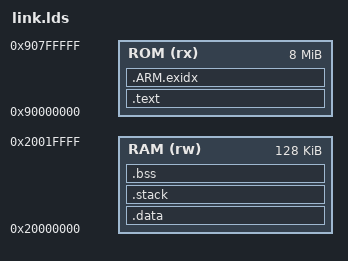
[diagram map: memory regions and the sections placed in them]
/*
 * linker script for STM32F4xx with GNU ld
 * bernard.xiong 2009-10-14
 */

/* Program Entry, set to mark it as "used" and avoid gc */
MEMORY
{
    /* XIP from external W25Q64 via QUADSPI memory-mapped window.            */
    /* Application is loaded by the bootloader at 0x08000000 which maps      */
    /* the QSPI flash here. See bootloader/src/w25q64.c.                     */
    ROM (rx) : ORIGIN = 0x90000000, LENGTH =    8M /* W25Q64: 8MB */
    RAM (rw) : ORIGIN = 0x20000000, LENGTH =  128k /* DTCM       */
}
ENTRY(Reset_Handler)
/* RT-Thread switches to per-thread stacks once scheduling starts, but the
 * startup stack must accommodate HAL_Init + SystemClock_Config (which calls
 * PeriphCommonClock_Config / HAL_RCCEx_PeriphCLKConfig / RCCEx_PLL2_Config /
 * HAL_GetTick nested) -- empirically ~700 bytes. The previous 0x200 limit
 * silently overflowed into the tail of .data (_object_container[Memory]),
 * which then made rt_smem_init's RT_ASSERT(information != NULL) fail. */
_system_stack_size = 0x800;

SECTIONS
{
    .text :
    {
        . = ALIGN(4);
        _stext = .;
        KEEP(*(.isr_vector))            /* Startup code */

        . = ALIGN(4);
        *(.text)                        /* remaining code */
        *(.text.*)                      /* remaining code */
        *(.rodata)                      /* read-only data (constants) */
        *(.rodata*)
        *(.glue_7)
        *(.glue_7t)
        *(.gnu.linkonce.t*)

        /* section information for finsh shell */
        . = ALIGN(4);
        __fsymtab_start = .;
        KEEP(*(FSymTab))
        __fsymtab_end = .;

        . = ALIGN(4);
        __vsymtab_start = .;
        KEEP(*(VSymTab))
        __vsymtab_end = .;

        /* section information for initial. */
        . = ALIGN(4);
        __rt_init_start = .;
        KEEP(*(SORT(.rti_fn*)))
        __rt_init_end = .;

        . = ALIGN(4);

        PROVIDE(__ctors_start__ = .);
        KEEP (*(SORT(.init_array.*)))
        KEEP (*(.init_array))
        PROVIDE(__ctors_end__ = .);

        . = ALIGN(4);

        _etext = .;
    } > ROM = 0

    /* .ARM.exidx is sorted, so has to go in its own output section.  */
    __exidx_start = .;
    .ARM.exidx :
    {
        *(.ARM.exidx* .gnu.linkonce.armexidx.*)

        /* This is used by the startup in order to initialize the .data secion */
        _sidata = .;
    } > ROM
    __exidx_end = .;

    /* .data section which is used for initialized data */

    .data : AT (_sidata)
    {
        . = ALIGN(4);
        /* This is used by the startup in order to initialize the .data secion */
        _sdata = . ;

        *(.data)
        *(.data.*)
        *(.gnu.linkonce.d*)

        PROVIDE(__dtors_start__ = .);
        KEEP(*(SORT(.dtors.*)))
        KEEP(*(.dtors))
        PROVIDE(__dtors_end__ = .);

        . = ALIGN(4);
        /* This is used by the startup in order to initialize the .data secion */
        _edata = . ;
    } >RAM

    .stack :
    {
        . = ALIGN(4);
        _sstack = .;
        . = . + _system_stack_size;
        . = ALIGN(4);
        _estack = .;
    } >RAM

    __bss_start = .;
    .bss :
    {
        . = ALIGN(4);
        /* This is used by the startup in order to initialize the .bss secion */
        _sbss = .;

        *(.bss)
        *(.bss.*)
        *(COMMON)

        . = ALIGN(4);
        /* This is used by the startup in order to initialize the .bss secion */
        _ebss = . ;

        *(.bss.init)
    } > RAM
    __bss_end = .;

    _end = .;

    /* Stabs debugging sections.  */
    .stab          0 : { *(.stab) }
    .stabstr       0 : { *(.stabstr) }
    .stab.excl     0 : { *(.stab.excl) }
    .stab.exclstr  0 : { *(.stab.exclstr) }
    .stab.index    0 : { *(.stab.index) }
    .stab.indexstr 0 : { *(.stab.indexstr) }
    .comment       0 : { *(.comment) }
    /* DWARF debug sections.
     * Symbols in the DWARF debugging sections are relative to the beginning
     * of the section so we begin them at 0.  */
    /* DWARF 1 */
    .debug          0 : { *(.debug) }
    .line           0 : { *(.line) }
    /* GNU DWARF 1 extensions */
    .debug_srcinfo  0 : { *(.debug_srcinfo) }
    .debug_sfnames  0 : { *(.debug_sfnames) }
    /* DWARF 1.1 and DWARF 2 */
    .debug_aranges  0 : { *(.debug_aranges) }
    .debug_pubnames 0 : { *(.debug_pubnames) }
    /* DWARF 2 */
    .debug_info     0 : { *(.debug_info .gnu.linkonce.wi.*) }
    .debug_abbrev   0 : { *(.debug_abbrev) }
    .debug_line     0 : { *(.debug_line) }
    .debug_frame    0 : { *(.debug_frame) }
    .debug_str      0 : { *(.debug_str) }
    .debug_loc      0 : { *(.debug_loc) }
    .debug_macinfo  0 : { *(.debug_macinfo) }
    /* SGI/MIPS DWARF 2 extensions */
    .debug_weaknames 0 : { *(.debug_weaknames) }
    .debug_funcnames 0 : { *(.debug_funcnames) }
    .debug_typenames 0 : { *(.debug_typenames) }
    .debug_varnames  0 : { *(.debug_varnames) }
}
